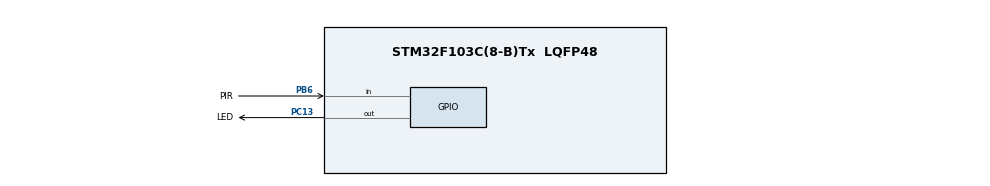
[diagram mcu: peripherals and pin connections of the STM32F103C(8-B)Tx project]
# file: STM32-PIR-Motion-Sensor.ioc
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Mcu.Family=STM32F1
Mcu.Name=STM32F103C(8-B)Tx
Mcu.Package=LQFP48
NVIC.PriorityGroup=NVIC_PRIORITYGROUP_4
PA13.Mode=JTAG_4_pins
PA13.Signal=SYS_JTMS-SWDIO
PA14.Mode=JTAG_4_pins
PA14.Signal=SYS_JTCK-SWCLK
PA15.Mode=JTAG_4_pins
PA15.Signal=SYS_JTDI
PB3.Mode=JTAG_4_pins
PB3.Signal=SYS_JTDO-TRACESWO
PB6.GPIO_Label=PIR
PB6.GPIO_PuPd=GPIO_PULLDOWN
PB6.Signal=GPIO_Input
PC13-TAMPER-RTC.GPIO_Label=LED
PC13-TAMPER-RTC.GPIO_ModeDefaultOutputPP=GPIO_MODE_OUTPUT_PP
PC13-TAMPER-RTC.GPIO_PuPd=GPIO_PULLUP
PC13-TAMPER-RTC.PinState=GPIO_PIN_SET
PC13-TAMPER-RTC.Signal=GPIO_Output
PC14-OSC32_IN.Mode=LSE-External-Oscillator
PC14-OSC32_IN.Signal=RCC_OSC32_IN
PC15-OSC32_OUT.Mode=LSE-External-Oscillator
PC15-OSC32_OUT.Signal=RCC_OSC32_OUT
ProjectManager.HeapSize=0x200
ProjectManager.StackSize=0x400
ProjectManager.TargetToolchain=STM32CubeIDE
RCC.APB1Freq_Value=8000000
RCC.APB2Freq_Value=8000000
board=custom

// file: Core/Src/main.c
/* USER CODE BEGIN Header */
/**
  ******************************************************************************
  * @file           : main.c
  * @brief          : Main program body
  ******************************************************************************
  * @attention
  *
  * <h2><center>&copy; Copyright (c) 2021 STMicroelectronics.
  * All rights reserved.</center></h2>
  *
  * This software component is licensed by ST under BSD 3-Clause license,
  * the "License"; You may not use this file except in compliance with the
  * License. You may obtain a copy of the License at:
  *                        opensource.org/licenses/BSD-3-Clause
  *
  ******************************************************************************
  */
/* USER CODE END Header */
#include "main.h"

/* USER CODE BEGIN Includes */
#include "stdio.h"
#include "pir_motion_sensor.h"
#include "led.h"
/* USER CODE END Includes */

void SystemClock_Config(void);
static void MX_GPIO_Init(void);

int main(void)
{

  /* MCU Configuration--------------------------------------------------------*/

  /* Reset of all peripherals, Initializes the Flash interface and the Systick. */
  HAL_Init();

  /* Configure the system clock */
  SystemClock_Config();

  /* Initialize all configured peripherals */
  MX_GPIO_Init();
  /* USER CODE BEGIN 2 */
  //PIR_Init();
  /* USER CODE END 2 */

  /* Infinite loop */
  while (1)
  {

    /* USER CODE BEGIN 3 */
	  PIRMotionSensor pir = get_PIR_status();
	  if (pir.status == 1)
	  {
		  LED_state(LED_ON);
	  } else {
		  LED_state(LED_OFF);
	  }
  }
  /* USER CODE END 3 */
}

void SystemClock_Config(void)
{
  RCC_OscInitTypeDef RCC_OscInitStruct = {0};
  RCC_ClkInitTypeDef RCC_ClkInitStruct = {0};

  /** Initializes the RCC Oscillators according to the specified parameters
  * in the RCC_OscInitTypeDef structure.
  */
  RCC_OscInitStruct.OscillatorType = RCC_OSCILLATORTYPE_HSI;
  RCC_OscInitStruct.HSIState = RCC_HSI_ON;
  RCC_OscInitStruct.HSICalibrationValue = RCC_HSICALIBRATION_DEFAULT;
  RCC_OscInitStruct.PLL.PLLState = RCC_PLL_NONE;
  if (HAL_RCC_OscConfig(&RCC_OscInitStruct) != HAL_OK)
  {
    Error_Handler();
  }

  /** Initializes the CPU, AHB and APB buses clocks
  */
  RCC_ClkInitStruct.ClockType = RCC_CLOCKTYPE_HCLK|RCC_CLOCKTYPE_SYSCLK
                              |RCC_CLOCKTYPE_PCLK1|RCC_CLOCKTYPE_PCLK2;
  RCC_ClkInitStruct.SYSCLKSource = RCC_SYSCLKSOURCE_HSI;
  RCC_ClkInitStruct.AHBCLKDivider = RCC_SYSCLK_DIV1;
  RCC_ClkInitStruct.APB1CLKDivider = RCC_HCLK_DIV1;
  RCC_ClkInitStruct.APB2CLKDivider = RCC_HCLK_DIV1;

  if (HAL_RCC_ClockConfig(&RCC_ClkInitStruct, FLASH_LATENCY_0) != HAL_OK)
  {
    Error_Handler();
  }
}

static void MX_GPIO_Init(void)
{
  GPIO_InitTypeDef GPIO_InitStruct = {0};

  /* GPIO Ports Clock Enable */
  __HAL_RCC_GPIOC_CLK_ENABLE();
  __HAL_RCC_GPIOA_CLK_ENABLE();
  __HAL_RCC_GPIOB_CLK_ENABLE();

  /*Configure GPIO pin Output Level */
  HAL_GPIO_WritePin(LED_GPIO_Port, LED_Pin, GPIO_PIN_SET);

  /*Configure GPIO pin : LED_Pin */
  GPIO_InitStruct.Pin = LED_Pin;
  GPIO_InitStruct.Mode = GPIO_MODE_OUTPUT_PP;
  GPIO_InitStruct.Pull = GPIO_PULLUP;
  GPIO_InitStruct.Speed = GPIO_SPEED_FREQ_LOW;
  HAL_GPIO_Init(LED_GPIO_Port, &GPIO_InitStruct);

  /*Configure GPIO pin : PIR_Pin */
  GPIO_InitStruct.Pin = PIR_Pin;
  GPIO_InitStruct.Mode = GPIO_MODE_INPUT;
  GPIO_InitStruct.Pull = GPIO_PULLDOWN;
  HAL_GPIO_Init(PIR_GPIO_Port, &GPIO_InitStruct);

}

void Error_Handler(void)
{
  /* USER CODE BEGIN Error_Handler_Debug */
  /* User can add his own implementation to report the HAL error return state */
  __disable_irq();
  while (1)
  {
	  HAL_PWR_EnterSTANDBYMode();
  }
  /* USER CODE END Error_Handler_Debug */
}
